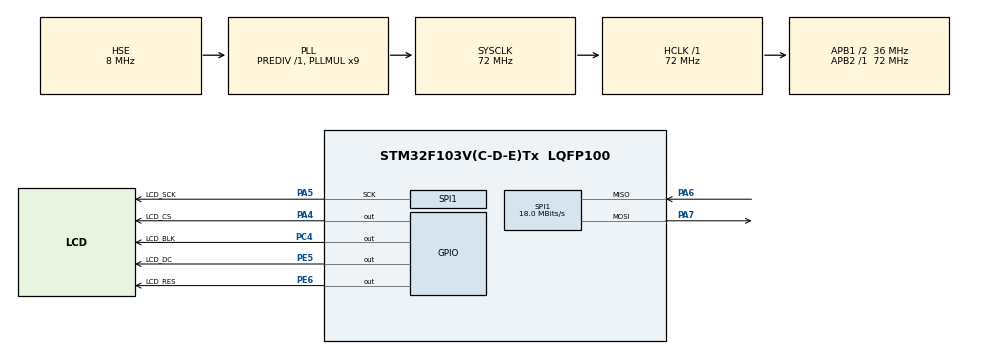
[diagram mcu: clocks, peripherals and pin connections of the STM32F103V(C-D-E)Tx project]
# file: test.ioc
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Dma.Request0=SPI1_RX
Dma.Request1=SPI1_TX
Dma.SPI1_RX.0.Direction=DMA_PERIPH_TO_MEMORY
Dma.SPI1_RX.0.Instance=DMA1_Channel2
Dma.SPI1_RX.0.MemDataAlignment=DMA_MDATAALIGN_BYTE
Dma.SPI1_RX.0.MemInc=DMA_MINC_ENABLE
Dma.SPI1_RX.0.Mode=DMA_NORMAL
Dma.SPI1_RX.0.PeriphDataAlignment=DMA_PDATAALIGN_BYTE
Dma.SPI1_RX.0.PeriphInc=DMA_PINC_DISABLE
Dma.SPI1_RX.0.Priority=DMA_PRIORITY_LOW
Dma.SPI1_TX.1.Direction=DMA_MEMORY_TO_PERIPH
Dma.SPI1_TX.1.Instance=DMA1_Channel3
Dma.SPI1_TX.1.MemDataAlignment=DMA_MDATAALIGN_BYTE
Dma.SPI1_TX.1.MemInc=DMA_MINC_ENABLE
Dma.SPI1_TX.1.Mode=DMA_NORMAL
Dma.SPI1_TX.1.PeriphDataAlignment=DMA_PDATAALIGN_BYTE
Dma.SPI1_TX.1.PeriphInc=DMA_PINC_DISABLE
Dma.SPI1_TX.1.Priority=DMA_PRIORITY_LOW
Mcu.Family=STM32F1
Mcu.Name=STM32F103V(C-D-E)Tx
Mcu.Package=LQFP100
NVIC.DMA1_Channel2_IRQn=true\:0\:0\:false\:false\:true\:false\:true\:true
NVIC.DMA1_Channel3_IRQn=true\:0\:0\:false\:false\:true\:false\:true\:true
NVIC.PriorityGroup=NVIC_PRIORITYGROUP_4
OSC_IN.Mode=HSE-External-Oscillator
OSC_IN.Signal=RCC_OSC_IN
OSC_OUT.Mode=HSE-External-Oscillator
OSC_OUT.Signal=RCC_OSC_OUT
PA13.Mode=Serial_Wire
PA13.Signal=SYS_JTMS-SWDIO
PA14.Mode=Serial_Wire
PA14.Signal=SYS_JTCK-SWCLK
PA4.GPIO_Label=LCD_CS
PA4.Signal=GPIO_Output
PA5.GPIO_Label=LCD_SCK
PA5.Mode=Full_Duplex_Master
PA5.Signal=SPI1_SCK
PA6.Mode=Full_Duplex_Master
PA6.Signal=SPI1_MISO
PA7.Mode=Full_Duplex_Master
PA7.Signal=SPI1_MOSI
PC4.GPIO_Label=LCD_BLK
PC4.Signal=GPIO_Output
PE5.GPIO_Label=LCD_DC
PE5.Signal=GPIO_Output
PE6.GPIO_Label=LCD_RES
PE6.Signal=GPIO_Output
ProjectManager.HeapSize=0x200
ProjectManager.StackSize=0x400
ProjectManager.TargetToolchain=STM32CubeIDE
RCC.AHBFreq_Value=72000000
RCC.APB1CLKDivider=RCC_HCLK_DIV2
RCC.APB1Freq_Value=36000000
RCC.APB1TimFreq_Value=72000000
RCC.APB2Freq_Value=72000000
RCC.APB2TimFreq_Value=72000000
RCC.HCLKFreq_Value=72000000
RCC.PLLMUL=RCC_PLL_MUL9
RCC.PLLSourceVirtual=RCC_PLLSOURCE_HSE
RCC.SYSCLKFreq_VALUE=72000000
RCC.SYSCLKSource=RCC_SYSCLKSOURCE_PLLCLK
RCC.USBFreq_Value=72000000
SPI1.BaudRatePrescaler=SPI_BAUDRATEPRESCALER_4
SPI1.CalculateBaudRate=18.0 MBits/s
SPI1.Direction=SPI_DIRECTION_2LINES
SPI1.Mode=SPI_MODE_MASTER
SPI1.VirtualType=VM_MASTER
board=custom

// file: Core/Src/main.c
/* USER CODE BEGIN Header */
/**
  ******************************************************************************
  * @file           : main.c
  * @brief          : Main program body
  ******************************************************************************
  * @attention
  *
  * Copyright (c) 2024 STMicroelectronics.
  * All rights reserved.
  *
  * This software is licensed under terms that can be found in the LICENSE file
  * in the root directory of this software component.
  * If no LICENSE file comes with this software, it is provided AS-IS.
  *
  ******************************************************************************
  */
/* USER CODE END Header */
#include "main.h"
#include "pic.h"

/* USER CODE BEGIN Includes */
#include "lcd.h"
/* USER CODE END Includes */

SPI_HandleTypeDef hspi1;
DMA_HandleTypeDef hdma_spi1_rx;
DMA_HandleTypeDef hdma_spi1_tx;

void SystemClock_Config(void);
static void MX_GPIO_Init(void);
static void MX_DMA_Init(void);
static void MX_SPI1_Init(void);

int main(void)
{

  /* MCU Configuration--------------------------------------------------------*/

  /* Reset of all peripherals, Initializes the Flash interface and the Systick. */
  HAL_Init();

  /* Configure the system clock */
  SystemClock_Config();

  /* Initialize all configured peripherals */
  MX_GPIO_Init();
  MX_DMA_Init();
  MX_SPI1_Init();
  /* USER CODE BEGIN 2 */
  LCD_Init();

  //LCD_Fill(0,0, 320, 480, BLUE);
	for(int j=0;j<7;j++)
	{
		for(int i=0;i<8;i++)
		{
			LCD_ShowPicture(40*i,200+j*40,40,40,gImage_1);
		}
	}
  /* USER CODE END 2 */

  /* Infinite loop */
  while (1)
  {

  }
}

void SystemClock_Config(void)
{
  RCC_OscInitTypeDef RCC_OscInitStruct = {0};
  RCC_ClkInitTypeDef RCC_ClkInitStruct = {0};

  /** Initializes the RCC Oscillators according to the specified parameters
  * in the RCC_OscInitTypeDef structure.
  */
  RCC_OscInitStruct.OscillatorType = RCC_OSCILLATORTYPE_HSE;
  RCC_OscInitStruct.HSEState = RCC_HSE_ON;
  RCC_OscInitStruct.HSEPredivValue = RCC_HSE_PREDIV_DIV1;
  RCC_OscInitStruct.HSIState = RCC_HSI_ON;
  RCC_OscInitStruct.PLL.PLLState = RCC_PLL_ON;
  RCC_OscInitStruct.PLL.PLLSource = RCC_PLLSOURCE_HSE;
  RCC_OscInitStruct.PLL.PLLMUL = RCC_PLL_MUL9;
  if (HAL_RCC_OscConfig(&RCC_OscInitStruct) != HAL_OK)
  {
    Error_Handler();
  }

  /** Initializes the CPU, AHB and APB buses clocks
  */
  RCC_ClkInitStruct.ClockType = RCC_CLOCKTYPE_HCLK|RCC_CLOCKTYPE_SYSCLK
                              |RCC_CLOCKTYPE_PCLK1|RCC_CLOCKTYPE_PCLK2;
  RCC_ClkInitStruct.SYSCLKSource = RCC_SYSCLKSOURCE_PLLCLK;
  RCC_ClkInitStruct.AHBCLKDivider = RCC_SYSCLK_DIV1;
  RCC_ClkInitStruct.APB1CLKDivider = RCC_HCLK_DIV2;
  RCC_ClkInitStruct.APB2CLKDivider = RCC_HCLK_DIV1;

  if (HAL_RCC_ClockConfig(&RCC_ClkInitStruct, FLASH_LATENCY_2) != HAL_OK)
  {
    Error_Handler();
  }
}

static void MX_SPI1_Init(void)
{

  /* SPI1 parameter configuration*/
  hspi1.Instance = SPI1;
  hspi1.Init.Mode = SPI_MODE_MASTER;
  hspi1.Init.Direction = SPI_DIRECTION_2LINES;
  hspi1.Init.DataSize = SPI_DATASIZE_8BIT;
  hspi1.Init.CLKPolarity = SPI_POLARITY_LOW;
  hspi1.Init.CLKPhase = SPI_PHASE_1EDGE;
  hspi1.Init.NSS = SPI_NSS_SOFT;
  hspi1.Init.BaudRatePrescaler = SPI_BAUDRATEPRESCALER_4;
  hspi1.Init.FirstBit = SPI_FIRSTBIT_MSB;
  hspi1.Init.TIMode = SPI_TIMODE_DISABLE;
  hspi1.Init.CRCCalculation = SPI_CRCCALCULATION_DISABLE;
  hspi1.Init.CRCPolynomial = 10;
  if (HAL_SPI_Init(&hspi1) != HAL_OK)
  {
    Error_Handler();
  }

}

static void MX_DMA_Init(void)
{

  /* DMA controller clock enable */
  __HAL_RCC_DMA1_CLK_ENABLE();

  /* DMA interrupt init */
  /* DMA1_Channel2_IRQn interrupt configuration */
  HAL_NVIC_SetPriority(DMA1_Channel2_IRQn, 0, 0);
  HAL_NVIC_EnableIRQ(DMA1_Channel2_IRQn);
  /* DMA1_Channel3_IRQn interrupt configuration */
  HAL_NVIC_SetPriority(DMA1_Channel3_IRQn, 0, 0);
  HAL_NVIC_EnableIRQ(DMA1_Channel3_IRQn);

}

static void MX_GPIO_Init(void)
{
  GPIO_InitTypeDef GPIO_InitStruct = {0};

  /* GPIO Ports Clock Enable */
  __HAL_RCC_GPIOE_CLK_ENABLE();
  __HAL_RCC_GPIOA_CLK_ENABLE();
  __HAL_RCC_GPIOC_CLK_ENABLE();

  /*Configure GPIO pin Output Level */
  HAL_GPIO_WritePin(GPIOE, LCD_DC_Pin|LCD_RES_Pin, GPIO_PIN_RESET);

  /*Configure GPIO pin Output Level */
  HAL_GPIO_WritePin(LCD_CS_GPIO_Port, LCD_CS_Pin, GPIO_PIN_RESET);

  /*Configure GPIO pin Output Level */
  HAL_GPIO_WritePin(LCD_BLK_GPIO_Port, LCD_BLK_Pin, GPIO_PIN_RESET);

  /*Configure GPIO pins : LCD_DC_Pin LCD_RES_Pin */
  GPIO_InitStruct.Pin = LCD_DC_Pin|LCD_RES_Pin;
  GPIO_InitStruct.Mode = GPIO_MODE_OUTPUT_PP;
  GPIO_InitStruct.Pull = GPIO_NOPULL;
  GPIO_InitStruct.Speed = GPIO_SPEED_FREQ_LOW;
  HAL_GPIO_Init(GPIOE, &GPIO_InitStruct);

  /*Configure GPIO pin : LCD_CS_Pin */
  GPIO_InitStruct.Pin = LCD_CS_Pin;
  GPIO_InitStruct.Mode = GPIO_MODE_OUTPUT_PP;
  GPIO_InitStruct.Pull = GPIO_NOPULL;
  GPIO_InitStruct.Speed = GPIO_SPEED_FREQ_LOW;
  HAL_GPIO_Init(LCD_CS_GPIO_Port, &GPIO_InitStruct);

  /*Configure GPIO pin : LCD_BLK_Pin */
  GPIO_InitStruct.Pin = LCD_BLK_Pin;
  GPIO_InitStruct.Mode = GPIO_MODE_OUTPUT_PP;
  GPIO_InitStruct.Pull = GPIO_NOPULL;
  GPIO_InitStruct.Speed = GPIO_SPEED_FREQ_LOW;
  HAL_GPIO_Init(LCD_BLK_GPIO_Port, &GPIO_InitStruct);

}

void Error_Handler(void)
{
  __disable_irq();
  while (1)
  {
  }
}
